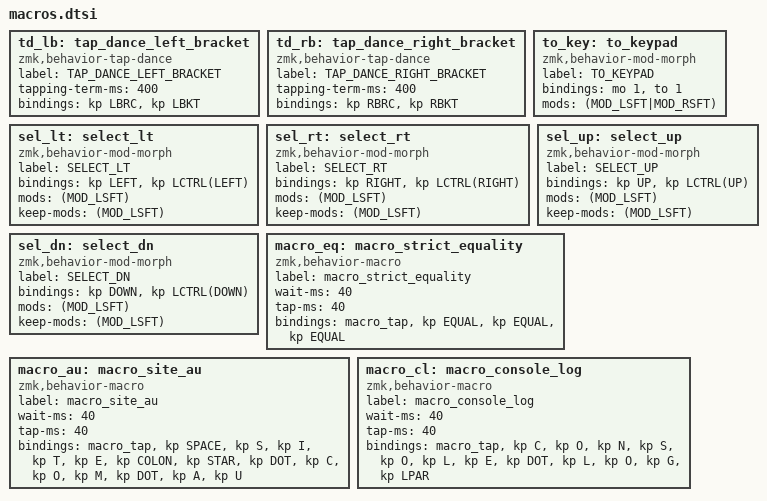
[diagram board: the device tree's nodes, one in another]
td_lb: tap_dance_left_bracket{
compatible = "zmk,behavior-tap-dance";
label = "TAP_DANCE_LEFT_BRACKET";
#binding-cells = <0>;
tapping-term-ms = <400>;
bindings = <&kp LBRC>, <&kp LBKT>;
};
td_rb: tap_dance_right_bracket{
compatible = "zmk,behavior-tap-dance";
label = "TAP_DANCE_RIGHT_BRACKET";
#binding-cells = <0>;
tapping-term-ms = <400>;
bindings = <&kp RBRC>, <&kp RBKT>;
};

to_key: to_keypad {
compatible = "zmk,behavior-mod-morph";
label = "TO_KEYPAD";
#binding-cells = <0>;
bindings = <&mo 1>, <&to 1>;
mods = <(MOD_LSFT|MOD_RSFT)>;
};
sel_lt: select_lt {
compatible = "zmk,behavior-mod-morph";
label = "SELECT_LT";
#binding-cells = <0>;
bindings = <&kp LEFT>, <&kp LCTRL(LEFT)>;
mods = <(MOD_LSFT)>;
keep-mods = <(MOD_LSFT)>;
};
sel_rt: select_rt {
compatible = "zmk,behavior-mod-morph";
label = "SELECT_RT";
#binding-cells = <0>;
bindings = <&kp RIGHT>, <&kp LCTRL(RIGHT)>;
mods = <(MOD_LSFT)>;
keep-mods = <(MOD_LSFT)>;
};
sel_up: select_up {
compatible = "zmk,behavior-mod-morph";
label = "SELECT_UP";
#binding-cells = <0>;
bindings = <&kp UP>, <&kp LCTRL(UP)>;
mods = <(MOD_LSFT)>;
keep-mods = <(MOD_LSFT)>;
};
sel_dn: select_dn {
compatible = "zmk,behavior-mod-morph";
label = "SELECT_DN";
#binding-cells = <0>;
bindings = <&kp DOWN>, <&kp LCTRL(DOWN)>;
mods = <(MOD_LSFT)>;
keep-mods = <(MOD_LSFT)>;
};

macro_eq: macro_strict_equality{
compatible = "zmk,behavior-macro";
label = "macro_strict_equality";
#binding-cells = <0>;
wait-ms = <40>;
tap-ms = <40>;
bindings = <&macro_tap &kp EQUAL &kp EQUAL &kp EQUAL>;
};
macro_au: macro_site_au{
compatible = "zmk,behavior-macro";
label = "macro_site_au";
#binding-cells = <0>;
wait-ms = <40>;
tap-ms = <40>;
bindings = <&macro_tap &kp SPACE &kp S &kp I &kp T &kp E &kp COLON &kp STAR &kp DOT &kp C &kp O &kp M &kp DOT &kp A &kp U>;
};
macro_cl: macro_console_log{
compatible = "zmk,behavior-macro";
label = "macro_console_log";
#binding-cells = <0>;
wait-ms = <40>;
tap-ms = <40>;
bindings = <&macro_tap &kp C &kp O &kp N &kp S &kp O &kp L &kp E &kp DOT &kp L &kp O &kp G &kp LPAR>;
};
